# RL6845_IP_SVD register map
Vendor: Realtek
Registers are 32-bit, read-write, reset 0x0 unless marked. A register's access mark holds for its fields unless they carry their own. Offsets are from the block's base; [hi:lo] are bit positions.

## I2C0_REG
Base 0x41108000
Same registers: I2C1_REG 0x4110A000
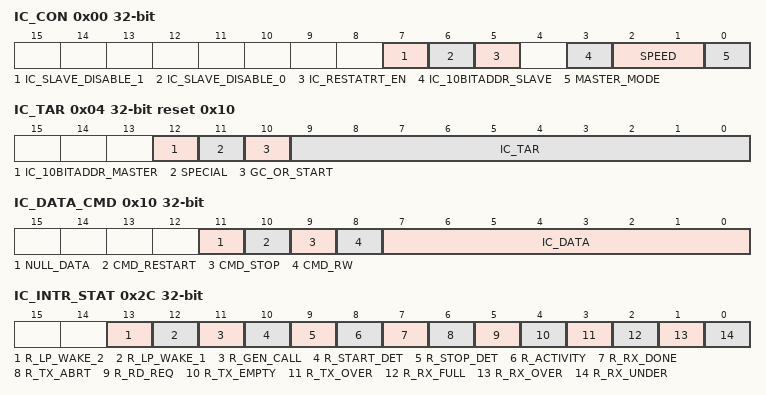
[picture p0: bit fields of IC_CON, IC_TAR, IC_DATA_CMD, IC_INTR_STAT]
0x00 IC_CON — I2C Control Register
  [7] IC_SLAVE_DISABLE_1 — This bit controls whether I2C has its slave2 (7-bit address) disabled. * 0: slave2 is enabled * 1: slave2 is disabled
  [6] IC_SLAVE_DISABLE_0 — This bit controls whether I2C has its slave1 (7-bit or 10-bit address) disabled. * 0: slave1 is enabled * 1: slave1 is disabled
  [5] IC_RESTATRT_EN — Determine whether RESTART conditions may be sent when acting as a master. * 0: disable * 1: enable
  [3] IC_10BITADDR_SLAVE — When acting as a slave, this bit controls whether the I2C responds to 7- or 10-bit addresses. * 0: 7-bit addressing * 1: 10-bit addressing
  [2:1] SPEED — These bits control at which speed the I2C operates; its setting is relevant only if one is operating the I2C in master mode. * 1: standard mode (0 to 100kbit/s) * 2: fast mode (<=400kbit/s) * 3: high speed mode (<=3.4Mbit/s)
  [0] MASTER_MODE — This bit controls whether the I2C master is enabled. * 0: master disabled * 1: master enabled
0x04 IC_TAR reset 0x10 — I2C Target Address Register
  [12] IC_10BITADDR_MASTER — Control whether I2C starts its transfers in 7- or 10-bit addressing mode when acting as a master. * 0: 7-bit addressing * 1: 10-bit addressing
  [11] SPECIAL — This bit indicates whether software performs a General Call or START BYTE command. * 0: ignore bit 10 GC_OR_START and use IC_TAR normally * 1: perform special I2C command as specified in GC_OR_START bit
  [10] GC_OR_START — If SPECIAL is set to 1, then this bit indicates whether a General Call or START BYTE command is to be performed by I2C. (ic_clk domain) * 0: General Call - after issuing a General Call, only write may be performed * 1: START BYTE
  [9:0] IC_TAR — This is the target address for any master transaction. When transmitting a General Call, these bits are ignored. To generate a START BYTE, the CPU needs to write only once into these bits.
0x08 IC_SAR reset 0x11 — I2C Slave Address Register
  [9:0] IC_SAR — The IC_SAR holds the slave address when the I2C is operating as slave1. For 7-bit addressing, only IC_SAR[6:0] is used. The register can be written only when the I2C interface is disabled, which corresponds to the IC_ENABLE register being set to 0. Writes at other times have no effect.
0x0C IC_HS_MAR — I2C High Speed Master Mode Code Address Register
  [2:0] IC_HS_MAR — This bit field holds the value of the I2C HS mode master code. HS-mode master codes are reserved 8-bit codes (00001xxx) that are not used for slave addressing or other purposes. This register can be written only when the I2C interface is disabled, which corresponds to the IC_ENABLE register being set to 0. Write at other times have no effect.
0x10 IC_DATA_CMD access per field — I2C Rx/Tx Data Buffer and Command Register
  [11] NULL_DATA wo — *1: null data transfer
  [10] CMD_RESTART wo — This bit controls whether a RESTART is issued after the byte is sent or received. * 1: a RESTART is issued after the data is sent/received (according to the value of CMD_RW), regardless of whether or not the transfer direction is changing from the previous command.
  [9] CMD_STOP wo — This bit controls whether a STOP is issued after the byte is sent or received. * 1: STOP is issued after this byte, regardless of whether or not the Tx FIFO is empty. If the Tx FIFO is not empty, the master immediately tries to start a new transfer by issuing a START and arbitrating for the bus. * 0: STOP is not issued after this byte.
  [8] CMD_RW wo — This bit controls whether a read or write is performed. This bit does not control the direction when the I2C acts as a slave. It controls only the direction when it acts as a master. * 1: Read * 0: Write
  [7:0] IC_DATA rw — This register contains the data to be transmitted or received on the I2C bus. If you are writing to this register and want to perform a read, these bits are ignored by the I2C. However, when you read this register, these bits return the value of data received on the I2C interface.
0x14 IC_SS_SCL_HCNT reset 0x190 — Standard Speed I2C Clock SCL High Count Register
  [15:0] IC_SS_SCL_HCNT — This register sets the SCL clock high-period count for standard speed. This register must be set before any I2C bus transaction can take place to ensure proper I/O timing. This register can be written only when the I2C interface is disabled which corresponds to the IC_ENABLE register being set to 0. Writes at other times have no effect.
0x18 IC_SS_SCL_LCNT reset 0x1D6 — Standard Speed I2C Clock SCL Low Count Register
  [15:0] IC_SS_SCL_LCNT — This register sets the SCL clock low-period count for standard speed. This register must be set before any I2C bus transaction can take place to ensure proper I/O timing. This register can be written only when the I2C interface is disabled which corresponds to the IC_ENABLE register being set to 0. Writes at other times have no effect.
0x1C IC_FS_SCL_HCNT reset 0x3C — Fast Speed I2C Clock SCL High Count Register
  [15:0] IC_FS_SCL_HCNT — This register sets the SCL clock high-period count for fast speed. This register must be set before any I2C bus transaction can take place to ensure proper I/O timing. This register can be written only when the I2C interface is disabled which corresponds to the IC_ENABLE register being set to 0. Writes at other times have no effect.
0x20 IC_FS_SCL_LCNT reset 0x82 — Fast Speed I2C Clock SCL Low Count Register
  [15:0] IC_FS_SCL_LCNT — This register sets the SCL clock low-period count for fast speed. This register must be set before any I2C bus transaction can take place to ensure proper I/O timing. This register can be written only when the I2C interface is disabled which corresponds to the IC_ENABLE register being set to 0. Writes at other times have no effect.
0x24 IC_HS_SCL_HCNT reset 0x6 — High Speed I2C Clock SCL High Count Register
  [15:0] IC_HS_SCL_HCNT — This register sets the SCL clock high-period count for high speed. This register must be set before any I2C bus transaction can take place to ensure proper I/O timing. This register can be written only when the I2C interface is disabled which corresponds to the IC_ENABLE register being set to 0. Writes at other times have no effect. The SCL High time depends on the loading of the bus. For 100pF loading, the SCL High time is 60ns; for 400pF loading, the SCL High time is 120ns.
0x28 IC_HS_SCL_LCNT reset 0x10 — High Speed I2C Clock SCL Low Count Register
  [15:0] IC_HS_SCL_LCNT — This register sets the SCL clock low-period count for high speed. This register must be set before any I2C bus transaction can take place to ensure proper I/O timing. This register can be written only when the I2C interface is disabled which corresponds to the IC_ENABLE register being set to 0. Writes at other times have no effect. The SCL Low time depends on the loading of the bus. For 100pF loading, the SCL High time is 160ns; for 400pF loading, the SCL High time is 320ns.
0x2C IC_INTR_STAT ro — I2C Interrupt Status Register
  [13] R_LP_WAKE_2 — Refer to I2C Raw Interrupt Status Register (IC_RAW_INTR_STAT) for a detailed description of this bit.
  [12] R_LP_WAKE_1 — Refer to I2C Raw Interrupt Status Register (IC_RAW_INTR_STAT) for a detailed description of this bit.
  [11] R_GEN_CALL — Refer to I2C Raw Interrupt Status Register (IC_RAW_INTR_STAT) for a detailed description of this bit.
  [10] R_START_DET — Refer to I2C Raw Interrupt Status Register (IC_RAW_INTR_STAT) for a detailed description of this bit.
  [9] R_STOP_DET — Refer to I2C Raw Interrupt Status Register (IC_RAW_INTR_STAT) for a detailed description of this bit.
  [8] R_ACTIVITY — Refer to I2C Raw Interrupt Status Register (IC_RAW_INTR_STAT) for a detailed description of this bit.
  [7] R_RX_DONE — Refer to I2C Raw Interrupt Status Register (IC_RAW_INTR_STAT) for a detailed description of this bit.
  [6] R_TX_ABRT — Refer to I2C Raw Interrupt Status Register (IC_RAW_INTR_STAT) for a detailed description of this bit.
  [5] R_RD_REQ — Refer to I2C Raw Interrupt Status Register (IC_RAW_INTR_STAT) for a detailed description of this bit.
  [4] R_TX_EMPTY — Refer to I2C Raw Interrupt Status Register (IC_RAW_INTR_STAT) for a detailed description of this bit.
  [3] R_TX_OVER — Refer to I2C Raw Interrupt Status Register (IC_RAW_INTR_STAT) for a detailed description of this bit.
  [2] R_RX_FULL — Refer to I2C Raw Interrupt Status Register (IC_RAW_INTR_STAT) for a detailed description of this bit.
  [1] R_RX_OVER — Refer to I2C Raw Interrupt Status Register (IC_RAW_INTR_STAT) for a detailed description of this bit.
  [0] R_RX_UNDER — Refer to I2C Raw Interrupt Status Register (IC_RAW_INTR_STAT) for a detailed description of this bit.
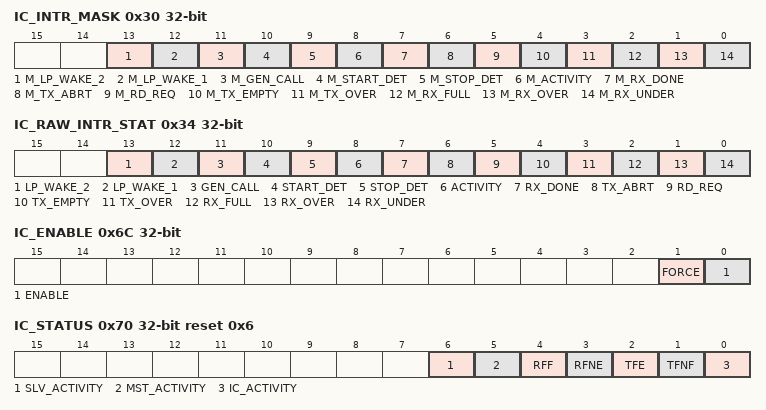
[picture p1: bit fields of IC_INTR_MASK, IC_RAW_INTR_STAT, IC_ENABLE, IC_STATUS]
0x30 IC_INTR_MASK — I2C Interrupt Mask Register
  [13] M_LP_WAKE_2 — This bit masks the corresponding interrupt status bit in the IC_INTR_STAT register.
  [12] M_LP_WAKE_1 — This bit masks the corresponding interrupt status bit in the IC_INTR_STAT register.
  [11] M_GEN_CALL — This bit masks the corresponding interrupt status bit in the IC_INTR_STAT register.
  [10] M_START_DET — This bit masks the corresponding interrupt status bit in the IC_INTR_STAT register.
  [9] M_STOP_DET — This bit masks the corresponding interrupt status bit in the IC_INTR_STAT register.
  [8] M_ACTIVITY — This bit masks the corresponding interrupt status bit in the IC_INTR_STAT register.
  [7] M_RX_DONE — This bit masks the corresponding interrupt status bit in the IC_INTR_STAT register.
  [6] M_TX_ABRT — This bit masks the corresponding interrupt status bit in the IC_INTR_STAT register.
  [5] M_RD_REQ — This bit masks the corresponding interrupt status bit in the IC_INTR_STAT register.
  [4] M_TX_EMPTY — This bit masks the corresponding interrupt status bit in the IC_INTR_STAT register.
  [3] M_TX_OVER — This bit masks the corresponding interrupt status bit in the IC_INTR_STAT register.
  [2] M_RX_FULL — This bit masks the corresponding interrupt status bit in the IC_INTR_STAT register.
  [1] M_RX_OVER — This bit masks the corresponding interrupt status bit in the IC_INTR_STAT register.
  [0] M_RX_UNDER — This bit masks the corresponding interrupt status bit in the IC_INTR_STAT register.
0x34 IC_RAW_INTR_STAT ro — I2C Raw Interrupt Status Register
  [13] LP_WAKE_2 — Set when address SAR_2 matches with address sending on I2C BUS.
  [12] LP_WAKE_1 — Set when address SAR matches with address sending on I2C BUS.
  [11] GEN_CALL — Set only when a General Call address is received and it is acknowledged.
  [10] START_DET — Indicate whether a START or RESTART condition has occurred on the I2C interface regardless of whether I2C is operating in slave or master mode.
  [9] STOP_DET — Indicate whether a STOP condition has occurred on the I2C interface regardless of whether I2C is operating in slave or master mode.
  [8] ACTIVITY — This bit captures I2C activity.
  [7] RX_DONE — When the I2C is acting as a slave-transmitter, this bit is set to 1 if the master does not acknowledge a transmitted byte. This occurs on the last byte of the transmission, indicating that the transmission is done.
  [6] TX_ABRT — This bit indicates if I2C as a transmitter, is unable to complete the intended actions on the contents of the transmit FIFO. This situation can occur both as an I2C master or an I2C slave, and is referred to as a 'transmit abort'. * 1: the IC_TX_ABRT_SOURCE register indicates the reason why the transmit abort take places.
  [5] RD_REQ — This bit is set to 1 when I2C is acting as a slave and another I2C master is attempting to read data from I2C. The I2C holds the I2C bus in a wait state (SCL=0) until this interrupt is serviced, which means that the slave has been addressed by a remote master that is asking for data to be transferred. The processor must respond to this interrupt and then write the requested data to the IC_DATA_CMD register.
  [4] TX_EMPTY — This bit is set to 1 when the transmit buffer is at or below the threshold value set in the IC_TX_TL register. It is automatically cleared by hardware when the buffer level goes above the threshold.
  [3] TX_OVER — Set during transmit if the transmit buffer is filled to IC_TX_BUFFER_DEPTH and the processor attempts to issue another I2C command by writing to the IC_DATA_CMD register.
  [2] RX_FULL — Set when the receive buffer goes above the RX_TL threshold in the IC_RX_TL register. It is automatically cleared by hardware when buffer level is equal to or less than the threshold.
  [1] RX_OVER — Not used. Set if the receive buffer is completely filled to IC_RX_BUFFER_DEPTH and an additional byte is received from an external I2C device.
  [0] RX_UNDER — Set if the processor attempts to read the receive buffer when it is empty by reading from the IC_DATA_CMD register.
0x38 IC_RX_TL — I2C Receive FIFO Threshold Register
  [7:0] IC_RX_0_TL — Receive FIFO Threshold Level. Control the level of entries (or above) that triggers the RX_FULL interrupt (bit[2] in IC_RAW_INTR_STAT register).
0x3C IC_TX_TL — I2C Transmit FIFO Threshold Register
  [7:0] IC_TX_0_TL — Transmit FIFO Threshold Level. Control the level of entries (or below) that triggers the TX_EMPTY interrupt (bit[4] in IC_RAW_INTR_STAT register).
0x40 IC_CLR_INTR ro — Clear Combined and Individual Interrupt Register
  [0] CLR_INRT — Read this register to clear the combined interrupt, all individual interrupts, and the IC_TX_ABRT_SOURCE register. This bit does not clear hardware clearable interrupts but software clearable interrupts.
0x44 IC_CLR_RX_UNDER ro — Clear RX_UNDER Interrupt Register
  [0] CLR_RX_UNDER — Read this register to clear the RX_UNDER interrupt (bit[0]) of IC_RAW_INTR_STAT register.
0x48 IC_CLR_RX_OVER ro — Clear RX_OVER Interrupt Register
  [0] CLR_RX_OVER — Read this register to clear the RX_OVER interrupt (bit[1]) of IC_RAW_INTR_STAT register.
0x4C IC_CLR_TX_OVER ro — Clear TX_OVER Interrupt Register
  [0] CLR_TX_OVER — Read this register to clear the TX_OVER interrupt (bit[3]) of IC_RAW_INTR_STAT register.
0x50 IC_CLR_RD_REQ ro — Clear RD_REQ Interrupt Register
  [0] CLR_RD_REQ — Read this register to clear the RD_REQ interrupt (bit[5]) of IC_RAW_INTR_STAT register.
0x54 IC_CLR_TX_ABRT ro — Clear TX_ABRT Interrupt Register
  [0] CLR_TX_ABRT — Read this register to clear the TX_ABRT interrupt (bit[6]) of IC_RAW_INTR_STAT register and the IC_TX_ABRT_SOURCE register. This also releases the TxFIFO from the flushed/reset state, allowing more writes to the Tx FIFO.
0x58 IC_CLR_RX_DONE ro — Clear RX_DONE Interrupt Register
  [0] CLR_RX_DONE — Read this register to clear the RX_DONE interrupt (bit[7]) of IC_RAW_INTR_STAT register.
0x5C IC_CLR_ACTIVITY ro — Clear ACTIVITY Interrupt Register
  [0] CLR_ACTIVITY — Read this register to clear the ACTIVITY interrupt if the I2C is not active anymore. If the I2C module is still active on the bus, the ACTIVITY interrupt bit continues to be set. It is automatically cleared by hardware if the module is disabled and if there is no further activity on the bus. The value read from this register to get status of the ACTIVITY interrupt (bit[8]) of the IC_RAW_INTR_STAT register.
0x60 IC_CLR_STOP_DET ro — Clear STOP_DET Interrupt Register
  [0] CLR_STOP_DET — Read this register to clear the STOP_DET interrupt (bit[9]) of IC_RAW_INTR_STAT register.
0x64 IC_CLR_START_DET ro — Clear START_DET Interrupt Register
  [0] CLR_START_DET — Read this register to clear the START_DET interrupt (bit[10]) of IC_RAW_INTR_STAT register.
0x68 IC_CLR_GEN_CALL ro — Clear GEN_ALL Interrupt Register
  [0] CLR_GEN_CALL — Read this register to clear the GEN_CALL interrupt (bit[11]) of IC_RAW_INTR_STAT register.
0x6C IC_ENABLE — I2C Enable Register
  [1] FORCE — Force master I2C stop transfer immediately after IC_ENABLE set 0. * 1: when IC_ENABLE is set 0 during transfer, force master FSM go to IDLE immediately. * 0: when IC_ENABLE is set 0 during transfer, master FSM while finish current transition (include RESTART) before go to IDLE.
  [0] ENABLE — Control whether the I2C is enabled. * 0: Disable I2C (Tx and Rx FIFOs are held in an erased state) * 1: Enable I2C
0x70 IC_STATUS ro reset 0x6 — I2C Status Register
  [6] SLV_ACTIVITY — Slave FSM Activity Status. When the Slave FSM is not in the IDLE state, this bit is set. * 0: Slave FSM is in the IDLE state so the slave part of I2C is not active * 1: Slave FSM is not he IDLE state so the slave part of I2C is active
  [5] MST_ACTIVITY — Master FSM Activity Status. When the Master FSM is not in the IDLE state, this bit is set. * 0: Master FSM is in the IDLE state so the master part of I2C is not active * 1: Master FSM is not he IDLE state so the master part of I2C is active
  [4] RFF — Receive FIFO Completely Full. When the receive FIFO is completely full, this bit is set. When the receive FIFO contains one or more empty location, this bit is cleared. * 0: Receive FIFO is not full * 1: Receive FIFO is full
  [3] RFNE — Receive FIFO Not Empty. This bit is set when the receive FIFO contains one or more entries; it is cleared when the receive FIFO is empty. * 0: Receive FIFO is empty * 1: Receive FIFO is not empty
  [2] TFE — Transmit FIFO Completely Empty. When the transmit FIFO is completely empty, this bit is set. When it contains one or more valid entries, this bit is cleared. This bit field does not request an interrupt. * 0: Transmit FIFO is not empty * 1: Transmit FIFO is empty
  [1] TFNF — Transmit FIFO Not Full. Set when the transmit FIFO contains one or more empty locations, and is cleared when the FIFO is full. * 0: Transmit FIFO is full * 1: Transmit FIFO is not full
  [0] IC_ACTIVITY — I2C Activity Status.
0x74 IC_TXFLR ro — I2C Transmit FIFO Level Register
  [5:0] TXFLR — Transmit FIFO Level. Contains the number of valid data entries in the transmit FIFO.
0x78 IC_RXFLR ro — I2C Receive FIFO Level Register
  [5:0] RXFLR — Receive FIFO Level. Contains the number of valid data entries in the receive FIFO.
0x7C IC_SDA_HOLD reset 0x1 — I2C SDA Hold Time Length Register
  [15:0] IC_SDA_HOLD — Set the required SDA hold time in units of ic_clk period.
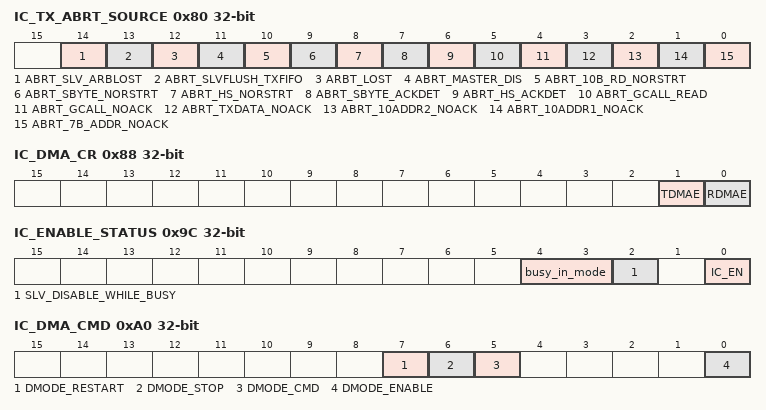
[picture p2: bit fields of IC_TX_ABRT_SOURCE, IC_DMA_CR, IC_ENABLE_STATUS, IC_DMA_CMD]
0x80 IC_TX_ABRT_SOURCE ro — I2C Transmit Abort Source Register
  [14] ABRT_SLV_ARBLOST — * 1: Slave losts the bus while transmitting data to a remote master. IC_TX_ABRT_SOURCE[12] is set at the same time.
  [13] ABRT_SLVFLUSH_TXFIFO — * 1: Slave has received a read command and some data exists in the TXFIFO so the slave issues a TX_ABRT interrupt to flush old data in Tx FIFO.
  [12] ARBT_LOST — * 1: Master has lost arbitration, or if IC_TX_ABRT_SOURCE[14] is also set, then the slave transmitter has lost arbitration.
  [11] ABRT_MASTER_DIS — * 1: User tries to initiate a Master operation with the master mode disabled.
  [10] ABRT_10B_RD_NORSTRT — * 1: The restart is disabled and the master sends a read command in 10-bit addressing mode.
  [9] ABRT_SBYTE_NORSTRT — * 1: The restart is disabled and the user is trying to send a START Byte.
  [8] ABRT_HS_NORSTRT — * 1: The restart is disabled and the user is trying to use the master to transfer data in High Speed mode.
  [7] ABRT_SBYTE_ACKDET — * 1: Master has send a START Byte and the START Byte was acknowledged (wrong behavior).
  [6] ABRT_HS_ACKDET — * 1: Master is in High Speed mode and the High Speed Master code was acknowledged (wrong behavior).
  [5] ABRT_GCALL_READ — * 1: I2C in master mode sents a General Call but the user programmed the byte following the General Call to be a read from the bus.
  [4] ABRT_GCALL_NOACK — * 1: I2C in master mode sents a General Call and no slave on the bus acknowledged the General Call.
  [3] ABRT_TXDATA_NOACK — * 1: This is a master-mode only bit. Master has received an acknowledgement for the address, but when it sent data byte(s) following the address, it did not receive an acknowledge from the remote slave(s).
  [2] ABRT_10ADDR2_NOACK — * 1: Master is in 10-bit address mode and the second byte of the 10-bit address was not acknowledged by any slave.
  [1] ABRT_10ADDR1_NOACK — * 1: Master is in 10-bit address mode and the first 10-bit address byte was not acknowledged by any slave.
  [0] ABRT_7B_ADDR_NOACK — * 1: Master is in 7-bit addressing mode and the address sent was not acknowledged by any slave
0x84 IC_SLV_DATA_NACK_ONLY — Generate Slave Data NACK Register
  [0] NACK — Generate NACK. This NACK generation only occurs when I2C is a slave-receiver. If this register is set to a value of 1, it can only generate a NACK after a data byte is received; hence, the data transfer is aborted and the data received is not pushed to the receive buffer. When the register is set to a value of 0, it generates NACK/ACK, depending on normal criteria. * 1: generate NACK after data byte received * 0: generate NACK/ACK normally
0x88 IC_DMA_CR — DMA Control Register
  [1] TDMAE — Transmit DMA Enable. This bit enables/disables the transmit FIFO DMA channel. * 0: Transmit DMA disabled * 1: Transmit DMA enabled
  [0] RDMAE — Receive DMA Enable. This bit enables/disables the receive FIFO DMA channel. * 0: Receive DMA disabled * 1: Receive DMA enabled
0x8C IC_DMA_TDLR — DMA Transmit Data Level Register
  [3:0] DMATDL — Transmit Data Level. This bit field controls the level at which a DMA request is made by the transmit logic. It is equal to the watermark level; that is, the dma_tx_req signal is generated when the number of valid data entries in the transmit FIFO is equal to or below this field value, and TDMAE=1.
0x90 IC_DMA_RDLR — I2C Receive Data Level Register
  [3:0] DMARDL — Receive Data Level. This bit field controls the level at which a DMA request is made by the receive logic. The watermark level=DMARDL+1; that is, the dma_tx_req signal is generated when the number of valid data entries in the receive FIFO is equal to or more than this field value+1, and RDMAE=1. For instance, when DMARDL is 0, the dma_rx_req is asserted when 1 or more data entries are present in the receive FIFO.
0x94 IC_SDA_SETUP reset 0x5 — I2C SDA Setup Register
  [7:0] IC_SDA_SETUP — Set the required SDA setup time in units of ic_clk period.
0x98 IC_ACK_GENERAL_CALL reset 0x1 — I2C ACK General Call Register
  [0] ACK_GEN_CALL — * 1: I2C responds with a ACK when it receives a General Call. * 0: I2C does not generate General Call interrupts.
0x9C IC_ENABLE_STATUS ro — I2C Enable Status Register
  [4:3] busy_in_mode — * 00: I2C is disable while busy in legacy mode. * 01: I2C is disable while busy in DMA mode. * 10: I2C is disable while busy in Descriptor mode.
  [2] SLV_DISABLE_WHILE_BUSY — Slave Disabled While Busy (Transmit, Receive). This bit indicates if a potential or active Slave operation has been aborted due to the setting of the IC_SLAVE_DISBALE register from 1 to 0.
  [0] IC_EN — IC_EN Status. This bit always reflects the value driven on the output port IC_EN. * 1: I2C is deemed to be in an enabled state. * 0: I2C is deemed completely inactive.
0xA0 IC_DMA_CMD access per field — I2C DMA Command Register
  [7] DMODE_RESTART rw — This bit controls whether a RESTART is issued after the byte is sent or received in DMA mode. * 1: a RESTART is issued after the data is sent/received (according to the value of CMD_RW), regardless of whether or not the transfer direction is changing from the previous command.
  [6] DMODE_STOP rw — This bit controls whether a STOP is issued after the byte is sent or received in DMA mode. * 1: STOP is issued after this byte, regardless of whether or not the Tx FIFO is empty. If the Tx FIFO is not empty, the master immediately tries to start a new transfer by issuing a START and arbitrating for the bus. * 0: STOP is not issued after this byte.
  [5] DMODE_CMD rw — This bit controls whether a read or write is performed in DMA mode. This bit does not control the direction when the I2C acts as a slave. It controls only the direction when it acts as a master. * 1: Read * 0: Write
  [0] DMODE_ENABLE wo — * 1: Set to enable DMA mode, cleared when transfer is done
0xA4 IC_DMA_DATA_LEN — I2C DMA Mode Transfer Data Length Register
  [15:0] DMA_DAT_LEN — DMA transfer data length
0xA8 IC_DMA_MODE — I2C DMA Mode Register
  [1:0] DMA_MODE — * 0: DWC DMA legacy mode * 1: DMA with control register * 2: DMA with transfer descriptor
0xB0 IC_DEBUG_SEL — I2C Debug SEL Register
  [3:0] IC_DEBUG_SEL — * 0: Debug clock * 1: Debug APB * 2: RSVD * 3: Debug FIFO * 4: Debug Timing * 5: Debug Slave Mode Address Match * 6: Debug Interrupt
0xB4 IC_OUT_SMP_DLY reset 0x2 — Sample Delay Register
  [2:0] IC_OUT_SMP_DLY — Delay cycles for sample of master derived SCL value. The sample of master derived SCL is used for slave stretch. Slave stretch is valid when master drive SCL High, but slave drive SCL low. Valid value of IC_OUT_SMP_DLY is 0-7. Inicate a delay of 1 to 8 cycles.
0xE4 IC_CLR_ADDR_MATCH ro — Clear Slave Mode Address Match Interrupt Register
  [0] IC_CLR_ADDR_MATCH — Read this register to clear the slave mode address match interrupt (bit[13:12]) of IC_RAW_INTR_STAT register.
0xE8 IC_CLR_DMA_DONE ro — Clear DMA DONE Interrupt Register
  [0] IC_CLR_RAW_INTR_STAT — Read this register to clear the DMA_DONE interrupt (bit[15]) of IC_RAW_INTR_STAT register.
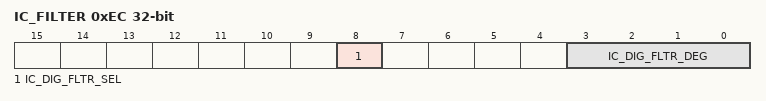
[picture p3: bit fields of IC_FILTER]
0xEC IC_FILTER — I2C Filter Register
  [8] IC_DIG_FLTR_SEL — 1: Enable filter
  [3:0] IC_DIG_FLTR_DEG — DIG_FLTR_DEG is to define frequency range of filter. A greater value of DIG_FLTR_DEG results in a slower transfer speed and hardware would be able to filter a lower frequency.
0xF4 IC_SAR2 reset 0x12 — I2C Slave2 Address Register
  [6:0] IC_SAR2 — The IC_SAR2 holds the slave address when the I2C is operating as slave2. Slave2 only supports 7-bit address. The register can be written only when the I2C interface is disabled, which corresponds to the IC_ENABLE register being set to 0. Writes at other times have no effect.
0xFC IC_COMP_VERSION ro reset 0x20200702 — I2C Component Version Register
  [31:0] IC_COMP_VERSION — I2C version number
0x100 IC_DUMMY ro
  [15:0] dummy — Reserved for HW
